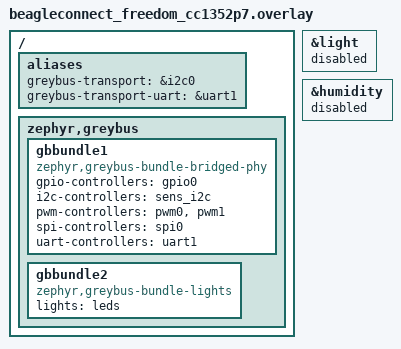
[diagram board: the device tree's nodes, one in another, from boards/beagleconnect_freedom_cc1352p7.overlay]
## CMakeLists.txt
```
# SPDX-License-Identifier: Apache-2.0

cmake_minimum_required(VERSION 3.20.0)

find_package(Zephyr REQUIRED HINTS $ENV{ZEPHYR_BASE})

project(greybus-basic)

target_sources(app PRIVATE src/main.c)

target_sources_ifdef(CONFIG_FAKE_CAMERA app PRIVATE ../../drivers/video/fake_camera.c)
```

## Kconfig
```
# Copyright (c) 2025 Ayush Singh, BeagleBoard.org
#
# SPDX-License-Identifier: Apache-2.0

mainmenu "Greybus basic sample"

config PRINT_MANIFEST
	bool "Print greybus manifest at startup"
	depends on GREYBUS
	help
	  Print greybus manifest at application startup

source "Kconfig.zephyr"
```

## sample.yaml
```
# Copyright (c) 2025, Ayush Singh, BeagleBoard.org
# SPDX-License-Identifier: Apache-2.0

sample:
  name: greybus-basic
  description: Basic sample using greybus service

tests:
  sample.greybus.basic.transport.dummy:
    build_only: true
    sysbuild: true
    platform_allow: beagleconnect_freedom@C7/cc1352p7
    extra_args: EXTRA_CONF_FILE="transport-dummy.conf"

  sample.greybus.basic.transport.tcpip:
    build_only: true
    sysbuild: true
    platform_allow: beagleconnect_freedom@C7/cc1352p7
    extra_args: EXTRA_CONF_FILE="transport-tcpip.conf;802154-subg.conf"

  sample.greybus.basic.transport.i2c:
    build_only: true
    sysbuild: true
    platform_allow: beagleconnect_freedom@C7/cc1352p7
    extra_args: EXTRA_CONF_FILE="transport-i2c.conf"

  sample.greybus.basic.transport.uart:
    build_only: true
    sysbuild: true
    platform_allow: beagleconnect_freedom@C7/cc1352p7
    extra_args: EXTRA_CONF_FILE="transport-uart.conf"
```

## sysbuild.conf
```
# Copyright (c) 2025 Ayush Singh, BeagleBoard.org
#
# SPDX-License-Identifier: Apache-2.0

# Enable MCUboot bootloader support
SB_CONFIG_BOOTLOADER_MCUBOOT=y
```

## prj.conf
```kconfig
# Copyright (c) 2025 Ayush Singh, BeagleBoard.org
#
# SPDX-License-Identifier: Apache-2.0

CONFIG_GREYBUS=y

CONFIG_LOG=y
CONFIG_GREYBUS_LOG_LEVEL_DBG=y
```

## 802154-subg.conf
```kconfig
# Copyright (c) 2025 Ayush Singh, BeagleBoard.org
#
# SPDX-License-Identifier: Apache-2.0

# Disable TCP and IPv4 (TCP disabled to avoid heavy traffic)
CONFIG_NET_IPV4=n

CONFIG_NET_CONFIG_NEED_IPV6=y
CONFIG_NET_CONFIG_NEED_IPV4=n
CONFIG_NET_CONFIG_MY_IPV4_ADDR=""
CONFIG_NET_CONFIG_PEER_IPV4_ADDR=""

CONFIG_NET_L2_IEEE802154=y

CONFIG_IEEE802154_CC13XX_CC26XX=n
CONFIG_NET_CONFIG_IEEE802154_CHANNEL=1
CONFIG_IEEE802154_CC13XX_CC26XX_SUB_GHZ=y
CONFIG_IEEE802154_CC13XX_CC26XX_SUB_GHZ_NUM_RX_BUF=8
```

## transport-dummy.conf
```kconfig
# Copyright (c) 2025 Ayush Singh, BeagleBoard.org
#
# SPDX-License-Identifier: Apache-2.0

CONFIG_GREYBUS_XPORT_DUMMY=y
CONFIG_PRINT_MANIFEST=y

# Having logging enabled causes messages to drop, thus causing parts of manifest to not print.
CONFIG_LOG=n
```

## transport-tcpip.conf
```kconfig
# Copyright (c) 2025 Ayush Singh, BeagleBoard.org
#
# SPDX-License-Identifier: Apache-2.0

# Generic networking options
CONFIG_NETWORKING=y
CONFIG_BT=n
CONFIG_NET_UDP=n
CONFIG_NET_TCP=y
CONFIG_NET_IPV6=y
CONFIG_NET_IPV4=y
CONFIG_NET_SOCKETS=y
CONFIG_NET_SOCKETS_POLL_MAX=16
CONFIG_ZVFS_OPEN_MAX=16
CONFIG_NET_CONNECTION_MANAGER=y
CONFIG_NET_MAX_CONN=16

# Service advertisement options
CONFIG_DNS_SD=y
CONFIG_NET_HOSTNAME_ENABLE=y
CONFIG_MDNS_RESPONDER=y
CONFIG_MDNS_RESPONDER_DNS_SD=y

# Kernel options
CONFIG_MAIN_STACK_SIZE=1024
CONFIG_ENTROPY_GENERATOR=y
CONFIG_INIT_STACKS=y

# Network buffers
CONFIG_NET_PKT_RX_COUNT=64
CONFIG_NET_PKT_TX_COUNT=32
CONFIG_NET_BUF_RX_COUNT=64
CONFIG_NET_BUF_TX_COUNT=32
CONFIG_NET_CONTEXT_NET_PKT_POOL=y

# IP address options
CONFIG_NET_IF_UNICAST_IPV6_ADDR_COUNT=3
CONFIG_NET_IF_MCAST_IPV6_ADDR_COUNT=4
CONFIG_NET_MAX_CONTEXTS=16

# Network application options and configuration
CONFIG_NET_CONFIG_SETTINGS=y
CONFIG_NET_CONFIG_MY_IPV6_ADDR="2001:db8::1"
CONFIG_NET_CONFIG_PEER_IPV6_ADDR="2001:db8::2"
CONFIG_NET_CONFIG_MY_IPV4_ADDR="192.0.2.1"
CONFIG_NET_CONFIG_PEER_IPV4_ADDR="192.0.2.2"
```

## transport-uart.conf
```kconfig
# Copyright (c) 2026 BeagleBoard.org
#
# SPDX-License-Identifier: Apache-2.0

CONFIG_GREYBUS_XPORT_UART=y
CONFIG_SERIAL=y
CONFIG_UART_INTERRUPT_DRIVEN=y
CONFIG_CRC=y
```

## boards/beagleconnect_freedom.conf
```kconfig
# Copyright (c) 2025 Ayush Singh, BeagleBoard.org
#
# SPDX-License-Identifier: Apache-2.0

CONFIG_GPIO=y
CONFIG_GPIO_GET_DIRECTION=y
CONFIG_GREYBUS_GPIO=y

CONFIG_I2C=y
CONFIG_GREYBUS_I2C=y

CONFIG_PWM=y
CONFIG_GREYBUS_PWM=y

CONFIG_SPI=y
CONFIG_GREYBUS_SPI=y

CONFIG_UART_LINE_CTRL=y
CONFIG_GREYBUS_UART=y

CONFIG_GREYBUS_LOOPBACK=y
CONFIG_GREYBUS_LOG_BACKEND=y

CONFIG_LED=y
CONFIG_GREYBUS_LIGHTS=y

CONFIG_FLASH=y
CONFIG_STREAM_FLASH=y
CONFIG_FLASH_MAP=y
CONFIG_BOOTLOADER_MCUBOOT=y
CONFIG_IMG_MANAGER=y
CONFIG_MCUBOOT_IMG_MANAGER=y
CONFIG_GREYBUS_FW=y

CONFIG_OPT3001=n
CONFIG_LIS2DH=n
CONFIG_LIS2DH_OPER_MODE_LOW_POWER=n
CONFIG_TI_HDC20XX=n
```

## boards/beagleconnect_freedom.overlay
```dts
/*
 * Copyright (c) 2025 Ayush Singh, BeagleBoard.org
 *
 * SPDX-License-Identifier: Apache-2.0
 */

/ {
	zephyr,greybus {
		gbbundle1 {
			status = "okay";
			compatible = "zephyr,greybus-bundle-bridged-phy";
			gpio-controllers = <&gpio0>;
			i2c-controllers = <&sens_i2c>;
			pwm-controllers = <&pwm0 &pwm1>;
			spi-controllers = <&spi0>;
			uart-controllers = <&uart1>;
		};

		gbbundle2 {
			status = "okay";
			compatible = "zephyr,greybus-bundle-lights";
			lights = <&leds>;
		};
	};
};
```

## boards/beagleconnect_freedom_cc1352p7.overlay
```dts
/*
 * Copyright (c) 2025 Ayush Singh, BeagleBoard.org
 *
 * SPDX-License-Identifier: Apache-2.0
 */

/ {
	aliases {
        	greybus-transport = &i2c0;
        	greybus-transport-uart = &uart1;
	};

	zephyr,greybus {
		gbbundle1 {
			status = "okay";
			compatible = "zephyr,greybus-bundle-bridged-phy";
			gpio-controllers = <&gpio0>;
			i2c-controllers = <&sens_i2c>;
			pwm-controllers = <&pwm0 &pwm1>;
			spi-controllers = <&spi0>;
			uart-controllers = <&uart1>;
		};

		gbbundle2 {
			status = "okay";
			compatible = "zephyr,greybus-bundle-lights";
			lights = <&leds>;
		};
	};
};

&light {
	status = "disabled";
};

&humidity {
	status = "disabled";
};
```

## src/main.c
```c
/*
 * Copyright (c) 2025 Ayush Singh BeagleBoard.org
 *
 * SPDX-License-Identifier: Apache-2.0
 */

#include <zephyr/sys/printk.h>

#ifdef CONFIG_PRINT_MANIFEST
#include "greybus-utils/manifest.h"
#endif // CONFIG_PRINT_MANIFEST

int main(void)
{
#ifdef CONFIG_PRINT_MANIFEST
	static char manifest[1024];

	int ret = manifest_create(manifest, ARRAY_SIZE(manifest));

	printk("Manifest Size: %d\n", ret);
	manifest_print(manifest);
#endif // CONFIG_PRINT_MANIFEST

	return 0;
}
```
